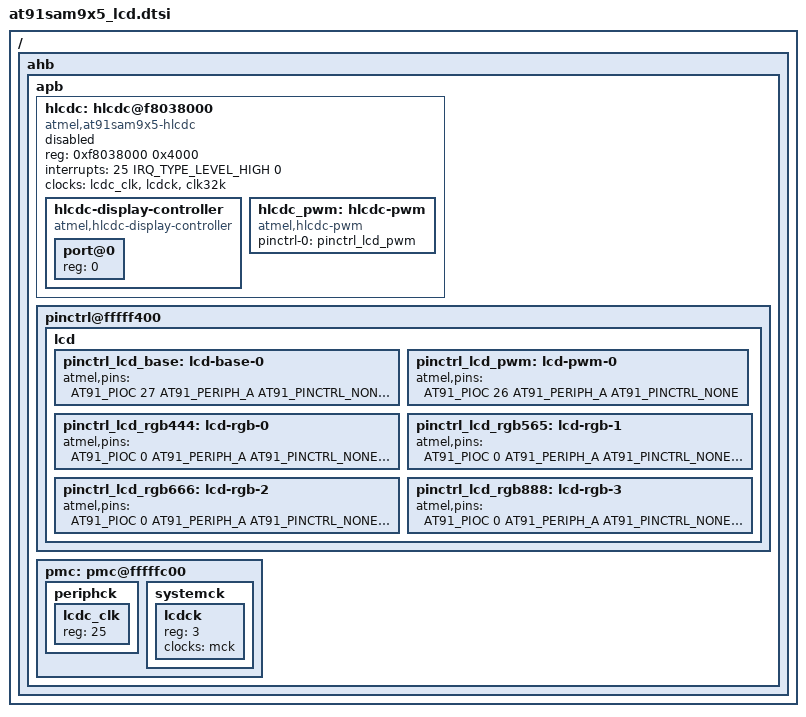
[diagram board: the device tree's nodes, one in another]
/*
 * at91sam9x5_lcd.dtsi - Device Tree Include file for AT91SAM9x5 SoC with an
 * LCD controller.
 *
 * Copyright (C) 2013 Boris BREZILLON <b.brezillon@overkiz.com>
 *
 * Licensed under GPLv2.
 */

#include <dt-bindings/pinctrl/at91.h>
#include <dt-bindings/interrupt-controller/irq.h>

/ {
	ahb {
		apb {
			hlcdc: hlcdc@f8038000 {
				compatible = "atmel,at91sam9x5-hlcdc";
				reg = <0xf8038000 0x4000>;
				interrupts = <25 IRQ_TYPE_LEVEL_HIGH 0>;
				clocks = <&lcdc_clk>, <&lcdck>, <&clk32k>;
				clock-names = "periph_clk","sys_clk", "slow_clk";
				status = "disabled";

				hlcdc-display-controller {
					compatible = "atmel,hlcdc-display-controller";
					#address-cells = <1>;
					#size-cells = <0>;

					port@0 {
						#address-cells = <1>;
						#size-cells = <0>;
						reg = <0>;
					};
				};

				hlcdc_pwm: hlcdc-pwm {
					compatible = "atmel,hlcdc-pwm";
					pinctrl-names = "default";
					pinctrl-0 = <&pinctrl_lcd_pwm>;
					#pwm-cells = <3>;
				};
			};

			pinctrl@fffff400 {
				lcd {
					pinctrl_lcd_base: lcd-base-0 {
						atmel,pins =
							<AT91_PIOC 27 AT91_PERIPH_A AT91_PINCTRL_NONE	/* LCDVSYNC */
							 AT91_PIOC 28 AT91_PERIPH_A AT91_PINCTRL_NONE	/* LCDHSYNC */
							 AT91_PIOC 24 AT91_PERIPH_A AT91_PINCTRL_NONE	/* LCDDISP */
							 AT91_PIOC 29 AT91_PERIPH_A AT91_PINCTRL_NONE	/* LCDDEN */
							 AT91_PIOC 30 AT91_PERIPH_A AT91_PINCTRL_NONE>;	/* LCDPCK */
					};

					pinctrl_lcd_pwm: lcd-pwm-0 {
						atmel,pins = <AT91_PIOC 26 AT91_PERIPH_A AT91_PINCTRL_NONE>;	/* LCDPWM */
					};

					pinctrl_lcd_rgb444: lcd-rgb-0 {
						atmel,pins =
							<AT91_PIOC 0 AT91_PERIPH_A AT91_PINCTRL_NONE	/* LCDD0 pin */
							 AT91_PIOC 1 AT91_PERIPH_A AT91_PINCTRL_NONE	/* LCDD1 pin */
							 AT91_PIOC 2 AT91_PERIPH_A AT91_PINCTRL_NONE	/* LCDD2 pin */
							 AT91_PIOC 3 AT91_PERIPH_A AT91_PINCTRL_NONE	/* LCDD3 pin */
							 AT91_PIOC 4 AT91_PERIPH_A AT91_PINCTRL_NONE	/* LCDD4 pin */
							 AT91_PIOC 5 AT91_PERIPH_A AT91_PINCTRL_NONE	/* LCDD5 pin */
							 AT91_PIOC 6 AT91_PERIPH_A AT91_PINCTRL_NONE	/* LCDD6 pin */
							 AT91_PIOC 7 AT91_PERIPH_A AT91_PINCTRL_NONE	/* LCDD7 pin */
							 AT91_PIOC 8 AT91_PERIPH_A AT91_PINCTRL_NONE	/* LCDD8 pin */
							 AT91_PIOC 9 AT91_PERIPH_A AT91_PINCTRL_NONE	/* LCDD9 pin */
							 AT91_PIOC 10 AT91_PERIPH_A AT91_PINCTRL_NONE	/* LCDD10 pin */
							 AT91_PIOC 11 AT91_PERIPH_A AT91_PINCTRL_NONE>;	/* LCDD11 pin */
					};

					pinctrl_lcd_rgb565: lcd-rgb-1 {
						atmel,pins =
							<AT91_PIOC 0 AT91_PERIPH_A AT91_PINCTRL_NONE	/* LCDD0 pin */
							 AT91_PIOC 1 AT91_PERIPH_A AT91_PINCTRL_NONE	/* LCDD1 pin */
							 AT91_PIOC 2 AT91_PERIPH_A AT91_PINCTRL_NONE	/* LCDD2 pin */
							 AT91_PIOC 3 AT91_PERIPH_A AT91_PINCTRL_NONE	/* LCDD3 pin */
							 AT91_PIOC 4 AT91_PERIPH_A AT91_PINCTRL_NONE	/* LCDD4 pin */
							 AT91_PIOC 5 AT91_PERIPH_A AT91_PINCTRL_NONE	/* LCDD5 pin */
							 AT91_PIOC 6 AT91_PERIPH_A AT91_PINCTRL_NONE	/* LCDD6 pin */
							 AT91_PIOC 7 AT91_PERIPH_A AT91_PINCTRL_NONE	/* LCDD7 pin */
							 AT91_PIOC 8 AT91_PERIPH_A AT91_PINCTRL_NONE	/* LCDD8 pin */
							 AT91_PIOC 9 AT91_PERIPH_A AT91_PINCTRL_NONE	/* LCDD9 pin */
							 AT91_PIOC 10 AT91_PERIPH_A AT91_PINCTRL_NONE	/* LCDD10 pin */
							 AT91_PIOC 11 AT91_PERIPH_A AT91_PINCTRL_NONE	/* LCDD11 pin */
							 AT91_PIOC 12 AT91_PERIPH_A AT91_PINCTRL_NONE	/* LCDD12 pin */
							 AT91_PIOC 13 AT91_PERIPH_A AT91_PINCTRL_NONE	/* LCDD13 pin */
							 AT91_PIOC 14 AT91_PERIPH_A AT91_PINCTRL_NONE	/* LCDD14 pin */
							 AT91_PIOC 15 AT91_PERIPH_A AT91_PINCTRL_NONE>;	/* LCDD15 pin */
					};

					pinctrl_lcd_rgb666: lcd-rgb-2 {
						atmel,pins =
							<AT91_PIOC 0 AT91_PERIPH_A AT91_PINCTRL_NONE	/* LCDD0 pin */
							 AT91_PIOC 1 AT91_PERIPH_A AT91_PINCTRL_NONE	/* LCDD1 pin */
							 AT91_PIOC 2 AT91_PERIPH_A AT91_PINCTRL_NONE	/* LCDD2 pin */
							 AT91_PIOC 3 AT91_PERIPH_A AT91_PINCTRL_NONE	/* LCDD3 pin */
							 AT91_PIOC 4 AT91_PERIPH_A AT91_PINCTRL_NONE	/* LCDD4 pin */
							 AT91_PIOC 5 AT91_PERIPH_A AT91_PINCTRL_NONE	/* LCDD5 pin */
							 AT91_PIOC 6 AT91_PERIPH_A AT91_PINCTRL_NONE	/* LCDD6 pin */
							 AT91_PIOC 7 AT91_PERIPH_A AT91_PINCTRL_NONE	/* LCDD7 pin */
							 AT91_PIOC 8 AT91_PERIPH_A AT91_PINCTRL_NONE	/* LCDD8 pin */
							 AT91_PIOC 9 AT91_PERIPH_A AT91_PINCTRL_NONE	/* LCDD9 pin */
							 AT91_PIOC 10 AT91_PERIPH_A AT91_PINCTRL_NONE	/* LCDD10 pin */
							 AT91_PIOC 11 AT91_PERIPH_A AT91_PINCTRL_NONE	/* LCDD11 pin */
							 AT91_PIOC 12 AT91_PERIPH_A AT91_PINCTRL_NONE	/* LCDD12 pin */
							 AT91_PIOC 13 AT91_PERIPH_A AT91_PINCTRL_NONE	/* LCDD13 pin */
							 AT91_PIOC 14 AT91_PERIPH_A AT91_PINCTRL_NONE	/* LCDD14 pin */
							 AT91_PIOC 15 AT91_PERIPH_A AT91_PINCTRL_NONE	/* LCDD15 pin */
							 AT91_PIOC 16 AT91_PERIPH_A AT91_PINCTRL_NONE	/* LCDD16 pin */
							 AT91_PIOC 17 AT91_PERIPH_A AT91_PINCTRL_NONE>;	/* LCDD17 pin */
					};

					pinctrl_lcd_rgb888: lcd-rgb-3 {
						atmel,pins =
							<AT91_PIOC 0 AT91_PERIPH_A AT91_PINCTRL_NONE	/* LCDD0 pin */
							 AT91_PIOC 1 AT91_PERIPH_A AT91_PINCTRL_NONE	/* LCDD1 pin */
							 AT91_PIOC 2 AT91_PERIPH_A AT91_PINCTRL_NONE	/* LCDD2 pin */
							 AT91_PIOC 3 AT91_PERIPH_A AT91_PINCTRL_NONE	/* LCDD3 pin */
							 AT91_PIOC 4 AT91_PERIPH_A AT91_PINCTRL_NONE	/* LCDD4 pin */
							 AT91_PIOC 5 AT91_PERIPH_A AT91_PINCTRL_NONE	/* LCDD5 pin */
							 AT91_PIOC 6 AT91_PERIPH_A AT91_PINCTRL_NONE	/* LCDD6 pin */
							 AT91_PIOC 7 AT91_PERIPH_A AT91_PINCTRL_NONE	/* LCDD7 pin */
							 AT91_PIOC 8 AT91_PERIPH_A AT91_PINCTRL_NONE	/* LCDD8 pin */
							 AT91_PIOC 9 AT91_PERIPH_A AT91_PINCTRL_NONE	/* LCDD9 pin */
							 AT91_PIOC 10 AT91_PERIPH_A AT91_PINCTRL_NONE	/* LCDD10 pin */
							 AT91_PIOC 11 AT91_PERIPH_A AT91_PINCTRL_NONE	/* LCDD11 pin */
							 AT91_PIOC 12 AT91_PERIPH_A AT91_PINCTRL_NONE	/* LCDD12 pin */
							 AT91_PIOC 13 AT91_PERIPH_A AT91_PINCTRL_NONE	/* LCDD13 pin */
							 AT91_PIOC 14 AT91_PERIPH_A AT91_PINCTRL_NONE	/* LCDD14 pin */
							 AT91_PIOC 15 AT91_PERIPH_A AT91_PINCTRL_NONE	/* LCDD15 pin */
							 AT91_PIOC 16 AT91_PERIPH_A AT91_PINCTRL_NONE	/* LCDD16 pin */
							 AT91_PIOC 17 AT91_PERIPH_A AT91_PINCTRL_NONE	/* LCDD17 pin */
							 AT91_PIOC 18 AT91_PERIPH_A AT91_PINCTRL_NONE	/* LCDD18 pin */
							 AT91_PIOC 19 AT91_PERIPH_A AT91_PINCTRL_NONE	/* LCDD19 pin */
							 AT91_PIOC 20 AT91_PERIPH_A AT91_PINCTRL_NONE	/* LCDD20 pin */
							 AT91_PIOC 21 AT91_PERIPH_A AT91_PINCTRL_NONE	/* LCDD21 pin */
							 AT91_PIOC 22 AT91_PERIPH_A AT91_PINCTRL_NONE	/* LCDD22 pin */
							 AT91_PIOC 23 AT91_PERIPH_A AT91_PINCTRL_NONE>;	/* LCDD23 pin */
					};
				};
			};

			pmc: pmc@fffffc00 {
				periphck {
					lcdc_clk: lcdc_clk {
						#clock-cells = <0>;
						reg = <25>;
					};
				};

				systemck {
					lcdck: lcdck {
						#clock-cells = <0>;
						reg = <3>;
						clocks = <&mck>;
					};
				};
			};
		};
	};
};
